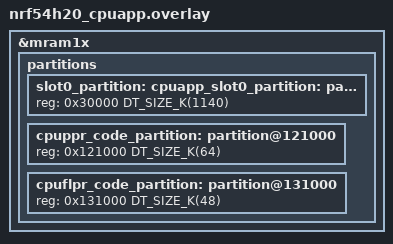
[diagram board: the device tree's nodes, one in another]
/*
 * Copyright (c) 2024 Nordic Semiconductor
 *
 * SPDX-License-Identifier: LicenseRef-Nordic-5-Clause
 */

/delete-node/ &cpuapp_boot_partition;
/delete-node/ &cpuapp_slot0_partition;
/delete-node/ &cpurad_slot0_partition;
/delete-node/ &cpuppr_code_partition;
/delete-node/ &cpuflpr_code_partition;
/delete-node/ &cpuapp_slot1_partition;
/delete-node/ &cpurad_slot1_partition;

&mram1x {
	partitions {
		slot0_partition: cpuapp_slot0_partition: partition@30000 {
			reg = <0x30000 DT_SIZE_K(1140)>;
		};

		cpuppr_code_partition: partition@121000 {
			reg = <0x121000 DT_SIZE_K(64)>;
		};

		cpuflpr_code_partition: partition@131000 {
			reg = <0x131000 DT_SIZE_K(48)>;
		};
	};
};
